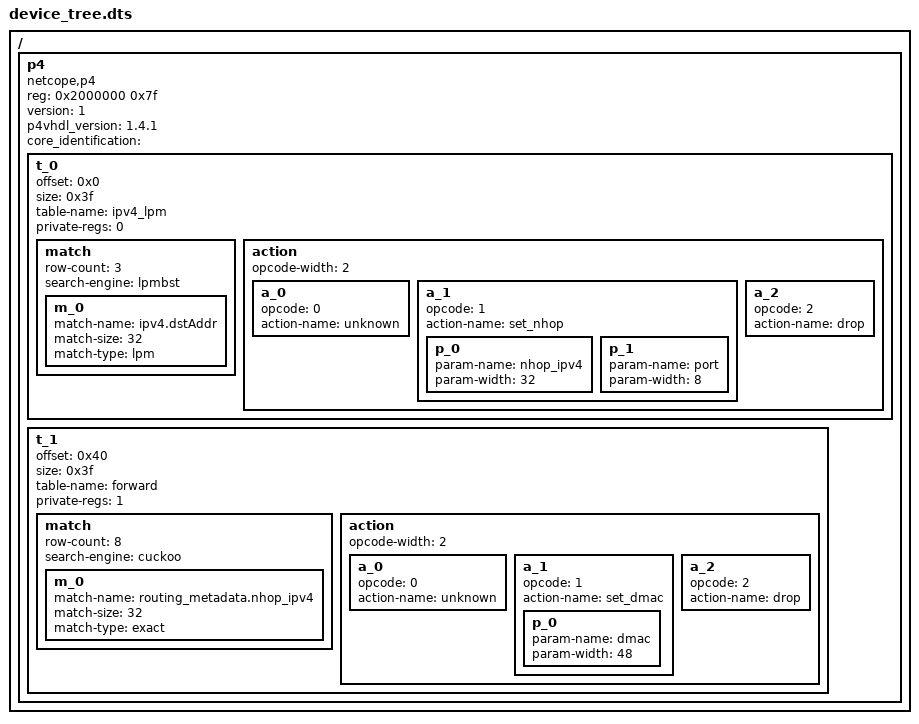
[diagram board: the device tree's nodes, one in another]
/dts-v1/;/ {
/*Root node of P4 device.*/
p4 {
   /*Basic address and size of address space*/
   /*Configuration of root MI32 switch*/
   reg=<0x2000000 0x7f>;

   /*Compatibility and version*/
   compatible="netcope,p4";
   version = <1>;
   p4vhdl_version = "1.4.1";
   core_identification=""; 


     t_0 {
          /*Configuration of MI32*/
          offset=<0x0>;
          size=<0x3f>;
          table-name = "ipv4_lpm";
          private-regs=<0>;

         /*Matching fields*/
         match {
            /* Number of rows in corresponding table */
            row-count=<3>;
            search-engine="lpmbst";

            /* Nodes with matches (no other subnodes --> no match fields) */
                m_0 {
                    match-name="ipv4.dstAddr";
                    match-size=<32>;
                    match-type="lpm";
                };

         };

          /*Actions (equals to positions in declaration)*/
          action {
             /*Width of the action opcode*/
             opcode-width=<2>;

                 a_0 {
                    /*Assigned opcode - used for mapping between the function's name and assigned opcode value*/
                    opcode=<0>;

                    /*Assigned action name*/
                    action-name = "unknown";

                     /*Nodes with parameters */
                 }; // End of action

                 a_1 {
                    /*Assigned opcode - used for mapping between the function's name and assigned opcode value*/
                    opcode=<1>;

                    /*Assigned action name*/
                    action-name = "set_nhop";

                     /*Nodes with parameters */
                         p_0 {
                             /*Parameters of the function
                                - param_name = list of strings where each name is mapped to variable in P4 program
                                - param_width = list of parameter widths (in bits)
                             */
                             param-name="nhop_ipv4";
                             param-width=<32>;
                         };

                         p_1 {
                             /*Parameters of the function
                                - param_name = list of strings where each name is mapped to variable in P4 program
                                - param_width = list of parameter widths (in bits)
                             */
                             param-name="port";
                             param-width=<8>;
                         };

                 }; // End of action

                 a_2 {
                    /*Assigned opcode - used for mapping between the function's name and assigned opcode value*/
                    opcode=<2>;

                    /*Assigned action name*/
                    action-name = "drop";

                     /*Nodes with parameters */
                 }; // End of action

          };



       };
     t_1 {
          /*Configuration of MI32*/
          offset=<0x40>;
          size=<0x3f>;
          table-name = "forward";
          private-regs=<1>;

         /*Matching fields*/
         match {
            /* Number of rows in corresponding table */
            row-count=<8>;
            search-engine="cuckoo";

            /* Nodes with matches (no other subnodes --> no match fields) */
                m_0 {
                    match-name="routing_metadata.nhop_ipv4";
                    match-size=<32>;
                    match-type="exact";
                };

         };

          /*Actions (equals to positions in declaration)*/
          action {
             /*Width of the action opcode*/
             opcode-width=<2>;

                 a_0 {
                    /*Assigned opcode - used for mapping between the function's name and assigned opcode value*/
                    opcode=<0>;

                    /*Assigned action name*/
                    action-name = "unknown";

                     /*Nodes with parameters */
                 }; // End of action

                 a_1 {
                    /*Assigned opcode - used for mapping between the function's name and assigned opcode value*/
                    opcode=<1>;

                    /*Assigned action name*/
                    action-name = "set_dmac";

                     /*Nodes with parameters */
                         p_0 {
                             /*Parameters of the function
                                - param_name = list of strings where each name is mapped to variable in P4 program
                                - param_width = list of parameter widths (in bits)
                             */
                             param-name="dmac";
                             param-width=<48>;
                         };

                 }; // End of action

                 a_2 {
                    /*Assigned opcode - used for mapping between the function's name and assigned opcode value*/
                    opcode=<2>;

                    /*Assigned action name*/
                    action-name = "drop";

                     /*Nodes with parameters */
                 }; // End of action

          };



       };
 };
};
